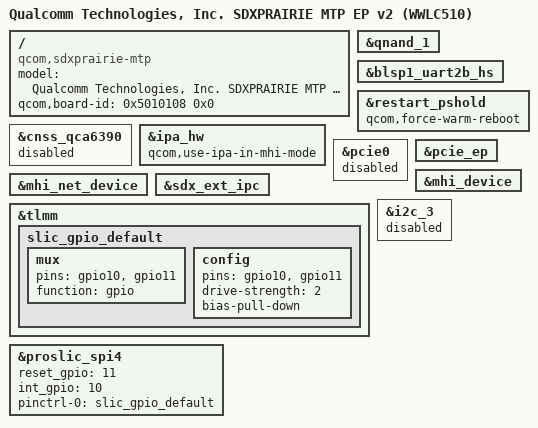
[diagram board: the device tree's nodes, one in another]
/* Copyright (c) 2018-2019, The Linux Foundation. All rights reserved.
 *
 * This program is free software; you can redistribute it and/or modify
 * it under the terms of the GNU General Public License version 2 and
 * only version 2 as published by the Free Software Foundation.
 *
 * This program is distributed in the hope that it will be useful,
 * but WITHOUT ANY WARRANTY; without even the implied warranty of
 * MERCHANTABILITY or FITNESS FOR A PARTICULAR PURPOSE.  See the
 * GNU General Public License for more details.
 */

/dts-v1/;

#include "sdxprairie-v2.dtsi"
#include "sdxprairie-mtp-wwlc510.dtsi"

/ {
	model = "Qualcomm Technologies, Inc. SDXPRAIRIE MTP EP v2 (WWLC510)";
	compatible = "qcom,sdxprairie-mtp",
		"qcom,sdxprairie", "qcom,mtp";
	qcom,board-id = <0x5010108 0x0>;
};

&qnand_1 {
	status = "ok";
};

&blsp1_uart2b_hs {
	status = "okay";
};

&restart_pshold {
        qcom,force-warm-reboot;
};

&cnss_qca6390 {
        status = "disabled";
};

&ipa_hw {
        qcom,use-ipa-in-mhi-mode;
};

&pcie0 {
        status = "disabled";
};

&pcie_ep {
        status = "ok";
};

&mhi_device {
        status = "ok";
};

&mhi_net_device {
        status = "okay";
};

&sdx_ext_ipc {
        status = "ok";
};

/* bruno@askey 20191023, suppport dts pinctrl to change GPIO alternate function */
/* for WWLC510 V2 module: SLIC_RST change from 91 to 11, SLIC_INT change from 90 to 10. 
   so need to change GPIO 10/11 alternate function from 4(I2C) to 0 (GPIO) */
&tlmm
{
	slic_gpio_default: slic_gpio_default {
		mux {
			pins = "gpio10", "gpio11";
			function = "gpio";
		};

		config {
			pins = "gpio10", "gpio11";
			drive-strength = <2>;
			bias-pull-down;
		};
	};
};

/* askey@bruno 20190516, for module, gpio 10 and 11 are used for SLIC INT/RST. */
&i2c_3 
{
  status = "disabled"; 
};

&proslic_spi4
{
	/* update gpio number */
	reset_gpio = <11>;
	int_gpio = <10>;
    
	/* bruno@askey 20191023, suppport dts pinctrl to change GPIO alternate function */
	pinctrl-names = "default";
	pinctrl-0 = <&slic_gpio_default>; 
};
